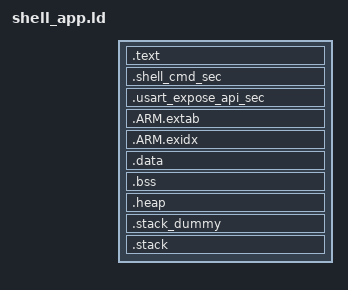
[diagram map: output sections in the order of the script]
OUTPUT_FORMAT ("elf32-littlearm", "elf32-bigarm", "elf32-littlearm")

SEARCH_DIR(.)
GROUP(-lgcc -lc -lnosys)

ENTRY(Reset_Handler)

INCLUDE memory.ld

SECTIONS
{
    .text :
    {
        KEEP(*(.isr_vector))
        *(.text*)

        KEEP(*(.init))
        KEEP(*(.fini))

        /* .ctors */
        *crtbegin.o(.ctors)
        *crtbegin?.o(.ctors)
        *(EXCLUDE_FILE(*crtend?.o *crtend.o) .ctors)
        *(SORT(.ctors.*))
        *(.ctors)

        /* .dtors */
        *crtbegin.o(.dtors)
        *crtbegin?.o(.dtors)
        *(EXCLUDE_FILE(*crtend?.o *crtend.o) .dtors)
        *(SORT(.dtors.*))
        *(.dtors)

        *(.rodata*)

        KEEP(*(.eh_frame*))
    } > shell_app_flash

    .shell_cmd_sec :
    {
      . = ALIGN(4);
      __shell_cmd_sec_start__ = .;
      KEEP(*(shell_cmd_sec))
      __shell_cmd_sec_end__ = .;
    } > shell_app_flash

    
    .usart_expose_api_sec :
    {
        . = ALIGN(16);
        __start_usart_expose_api = .;
        KEEP(*(usart_expose_api_sec))
    } > shell_app_flash

    .ARM.extab :
    {
        *(.ARM.extab* .gnu.linkonce.armextab.*)
    } > shell_app_flash

    __exidx_start = .;
    .ARM.exidx :
    {
        *(.ARM.exidx* .gnu.linkonce.armexidx.*)
    } > shell_app_flash
    __exidx_end = .;

    . = ALIGN(4);
    __etext = .;

    .data : AT (__etext)
    {
        __data_start__ = .;
        *(vtable)
        *(.data*)

        . = ALIGN(4);
        /* preinit data */
        PROVIDE_HIDDEN (__preinit_array_start = .);
        KEEP(*(.preinit_array))
        PROVIDE_HIDDEN (__preinit_array_end = .);

        . = ALIGN(4);
        /* init data */
        PROVIDE_HIDDEN (__init_array_start = .);
        KEEP(*(SORT(.init_array.*)))
        KEEP(*(.init_array))
        PROVIDE_HIDDEN (__init_array_end = .);


        . = ALIGN(4);
        /* finit data */
        PROVIDE_HIDDEN (__fini_array_start = .);
        KEEP(*(SORT(.fini_array.*)))
        KEEP(*(.fini_array))
        PROVIDE_HIDDEN (__fini_array_end = .);

        KEEP(*(.jcr*))
        . = ALIGN(4);
        /* All data end */
        __data_end__ = .;

    } > shell_app_ram

    .bss :
    {
        . = ALIGN(4);
        __bss_start__ = .;
        *(.bss*)
        *(COMMON)
        . = ALIGN(4);
        __bss_end__ = .;
    } > shell_app_ram
    
    .heap (COPY):
    {
        __HeapBase = .;
        __end__ = .;
        PROVIDE(end = .);
        KEEP(*(.heap*))
        __HeapLimit = .;
    } > shell_app_ram

    /* .stack_dummy section doesn't contains any symbols. It is only
     * used for linker to calculate size of stack sections, and assign
     * values to stack symbols later */
    .stack_dummy (COPY):
    {
        KEEP(*(.stack*))
    } > shell_app_ram

    /* Set stack top to end of RAM, and stack limit move down by
     * size of stack_dummy section */
    __StackTop = ORIGIN(shell_app_ram) + LENGTH(shell_app_ram);
    __StackLimit = __StackTop - SIZEOF(.stack_dummy);
    PROVIDE(__stack = __StackTop);

     .stack (NOLOAD):
    {
        . = ALIGN(8);
        _sstack = .;
        . = . + 0x2000;
        . = ALIGN(8);
        _estack = .;
    } > shell_app_ram

    . = ALIGN(4);
    _end = . ;
}

